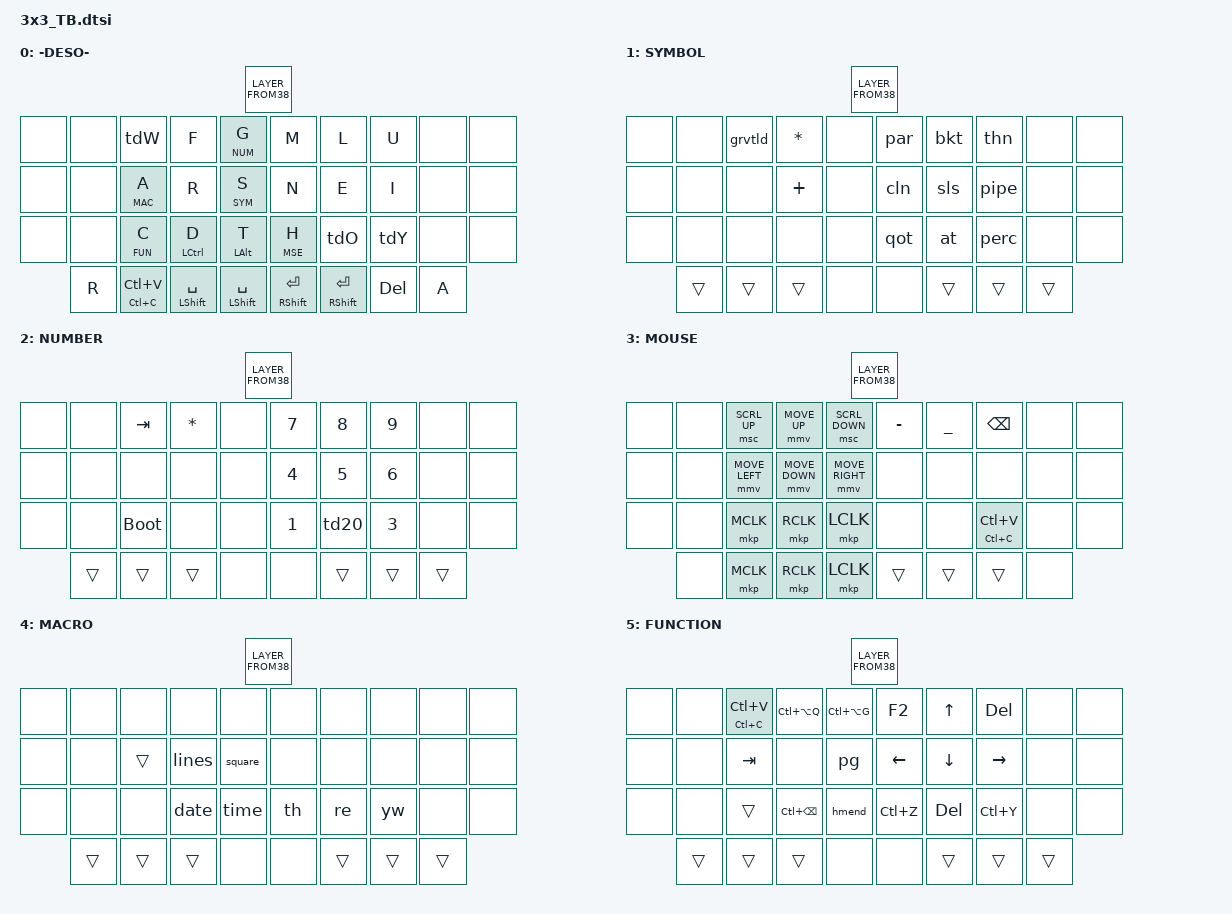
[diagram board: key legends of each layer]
/*
 * Last Update 10/5/24
 * 3 COL - 4 thumb keys per side
 * 
 */
 
#include <behaviors.dtsi>
#include <dt-bindings/zmk/keys.h>
#include <dt-bindings/zmk/bt.h>
#include <dt-bindings/zmk/outputs.h>
#include <dt-bindings/zmk/mouse.h>
#include "combos.dtsi"
#ifdef MOUSE_KEYS
#    include "mouse.dtsi"
#    define MS_ACT(key) &lt MSE key
#else
#    define MS_ACT(key) &kp key
#endif

// Layer aliases
#define DEF 0
#define SYM 1
#define NUM 2
#define MSE 3
#define MAC 4
#define FUN 5


&mt {
    flavor = "hold-preferred";
    tapping-term-ms = <160>;
};

&lt {
    flavor = "balanced";
    tapping-term-ms = <150>;
};

/ {
    behaviors {

        bkt: tap_dance_bracket {
            compatible = "zmk,behavior-tap-dance";
            label = "tap_dance_bracket";
            #binding-cells = <0>;
            tapping-term-ms = <200>;
            bindings = <&kp LBKT>, <&kp RBKT>;
        };

        cln: tap_dance_colon {
            compatible = "zmk,behavior-tap-dance";
            label = "tap_dance_colon";
            #binding-cells = <0>;
            tapping-term-ms = <200>;
            bindings = <&kp COLON>, <&kp SEMI>;
        };

        par: tap_dance_paren {
            compatible = "zmk,behavior-tap-dance";
            label = "tap_dance_paren";
            #binding-cells = <0>;
            tapping-term-ms = <200>;
            bindings = <&kp LPAR>, <&kp RPAR>;
        };

        thn: tap_dance_then {
            compatible = "zmk,behavior-tap-dance";
            label = "tap_dance_then";
            #binding-cells = <0>;
            tapping-term-ms = <200>;
            bindings = <&kp LT>, <&kp GT>;
        };

        qot: tap_dance_quote {
            compatible = "zmk,behavior-tap-dance";
            label = "tap_dance_quote";
            #binding-cells = <0>;
            tapping-term-ms = <200>;
            bindings = <&kp SQT>, <&kp DQT>;
        };

        sls: tap_dance_slash {
            compatible = "zmk,behavior-tap-dance";
            label = "tap_dance_slash";
            #binding-cells = <0>;
            tapping-term-ms = <200>;
            bindings = <&kp FSLH>, <&kp BSLH>;
        };

        pipe: tap_dance_pipe {
            compatible = "zmk,behavior-tap-dance";
            label = "tap_dance_pipe";
            #binding-cells = <0>;
            tapping-term-ms = <200>;
            bindings = <&kp PIPE>, <&kp AMPS>;
        };

        at: tap_dance_at {
            compatible = "zmk,behavior-tap-dance";
            label = "tap_dance_at";
            #binding-cells = <0>;
            tapping-term-ms = <200>;
            bindings = <&kp AT>, <&kp HASH>;
        };

        grvtld: tap_dance_gravetilde {
            compatible = "zmk,behavior-tap-dance";
            label = "tap_dance_gravetilde";
            #binding-cells = <0>;
            tapping-term-ms = <200>;
            bindings = <&kp GRAVE>, <&kp TILDE>;
        };

        perc: tap_dance_perc {
            compatible = "zmk,behavior-tap-dance";
            label = "tap_dance_perc";
            #binding-cells = <0>;
            tapping-term-ms = <200>;
            bindings = <&kp PRCNT>, <&kp DLLR>;
        };

        pg: tap_dance_pg {
            compatible = "zmk,behavior-tap-dance";
            label = "tap_dance_pg";
            #binding-cells = <0>;
            tapping-term-ms = <200>;
            bindings = <&kp PG_DN>, <&kp PG_UP>;
        };

        hmend: tap_dance_hmend {
            compatible = "zmk,behavior-tap-dance";
            label = "tap_dance_hmend";
            #binding-cells = <0>;
            tapping-term-ms = <200>;
            bindings = <&kp END>, <&kp HOME>;
        };

        tdW: tap_dance_W {
            compatible = "zmk,behavior-tap-dance";
            #binding-cells = <0>;
            tapping-term-ms = <180>;
            bindings = <&kp W>, <&kp ESC>;
        };

        tdO: tap_dance_O {
            compatible = "zmk,behavior-tap-dance";
            #binding-cells = <0>;
            tapping-term-ms = <200>;
            bindings = <&kp O>, <&kp COMMA>;
        };

        tdY: tap_dance_Y {
            compatible = "zmk,behavior-tap-dance";
            #binding-cells = <0>;
            tapping-term-ms = <200>;
            bindings = <&kp Y>, <&kp DOT>;
        };

        td20: tap_dance_20 {
            compatible = "zmk,behavior-tap-dance";
            #binding-cells = <0>;
            tapping-term-ms = <200>;
            bindings = <&kp N2>, <&kp N0>;
        };

        cccv: copy_paste {
           compatible = "zmk,behavior-hold-tap";
           #binding-cells = <2>;
           flavor = "hold-preferred";
           tapping-term-ms = <200>;
            bindings = <&kp>, <&kp>;
        };

        hrm: homerow_mods {
            compatible = "zmk,behavior-hold-tap";
            #binding-cells = <2>;
            tapping-term-ms = <200>;
            quick-tap-ms = <0>;
            flavor = "tap-preferred";
            bindings = <&kp>, <&kp>;
        };
    };

    macros {
        th: ahk_th {
            compatible = "zmk,behavior-macro";
            #binding-cells = <0>;
            bindings
                = <&macro_tap &kp FSLH &kp FSLH &kp T &kp H>
                ;
        };

        re: ahk_re {
            compatible = "zmk,behavior-macro";
            #binding-cells = <0>;
            bindings
                = <&macro_tap &kp FSLH &kp FSLH &kp R &kp E>
                ;
        };

        yw: ahk_yw {
            compatible = "zmk,behavior-macro";
            #binding-cells = <0>;
            bindings
                = <&macro_tap &kp FSLH &kp FSLH &kp Y &kp W>
                ;
        };

        date: ahk_date {
            compatible = "zmk,behavior-macro";
            #binding-cells = <0>;
            bindings
                = <&macro_tap &kp FSLH &kp FSLH &kp A &kp N1 &kp N1>
                ;
        };

        time: ahk_time {
            compatible = "zmk,behavior-macro";
            #binding-cells = <0>;
            bindings
                = <&macro_tap &kp FSLH &kp FSLH &kp A &kp N1 &kp N2>
                ;
        };

        lines: ahk_lines {
            compatible = "zmk,behavior-macro";
            #binding-cells = <0>;
            bindings
                = <&macro_tap &kp FSLH &kp FSLH &kp A &kp N0 &kp N8>
                ;
        };

        square: ahk_square {
            compatible = "zmk,behavior-macro";
            #binding-cells = <0>;
            bindings
                = <&macro_tap &kp FSLH &kp FSLH &kp A &kp N0 &kp N9>
                ;
        };
    };

    keymap {
        compatible = "zmk,keymap";


// ---------------------------------------------------------------------------------------------------------------
// |   TAB   |    W   [Q]   F   [B]   G num|         |    X    |         |    M   [J]   L    |    U    |  BSPC   |
// |  SHIFT  | A macro[V]   R   [P]   S sym|         |    X    |         |    N   [K]   E   [!]   I    |  DEL    |
// |  XXXX   |  C  fn [Z]   D   [X]   T    |         |    X    |         | H mouse |  O tt,  |  Y  tt. |  XXXX   |
//                     |   CCCV  |SPC/SHFT | RETURN  |    X    |   SPC   | SPC/ENT |   Paste |
// ---------------------------------------------------------------------------------------------------------------
        default_layer {
            display-name = "-DESO-";            
            bindings = <LAYER_FROM38( \
                &none, &none, &tdW, &kp F, &lt NUM G, &kp M, &kp L, &kp U, &none, &none, \
                &none, &none, &lt MAC A, &kp R, &lt SYM S, &kp N, &kp E, &kp I, &none, &none, \
                &none, &none, &lt FUN C, &hrm LCTRL D, &hrm LALT T, &lt MSE H, &tdO, &tdY, &none, &none, \
                &kp R, &cccv LC(C) LC(V), &mt LSHIFT SPC, &mt LSHIFT SPC, &mt RSHIFT RET, &mt RSHIFT RET,  &kp DEL, &kp A \
            )>;
        };

        SYM_layer {
            display-name = "SYMBOL";
            bindings = <LAYER_FROM38( \
                &none, &none, &grvtld, &kp STAR, &none, &par, &bkt, &thn, &none, &none, \
                &none, &none, &none, &kp PLUS, &none, &cln, &sls, &pipe, &none, &none, \
                &none, &none, &none, &none, &none, &qot, &at, &perc, &none, &none, \
                &trans, &trans, &trans, &none, &none, &trans, &trans,  &trans \
            )>;
        };

        NUM_layer {
            display-name = "NUMBER";
            bindings = <LAYER_FROM38( \
                &none, &none, &kp TAB, &kp STAR, &none, &kp N7, &kp N8, &kp N9, &none, &none, \
                &none, &none, &none, &none, &none, &kp N4, &kp N5, &kp N6, &none, &none, \
                &none, &none, &bootloader, &none, &none, &kp N1, &td20, &kp N3, &none, &none, \
                       &trans, &trans, &trans, &none, &none, &trans, &trans, &trans \
            )>;
        };

        MOUSE_layer {
            display-name = "MOUSE";
            bindings = <LAYER_FROM38( \
                &none, &none, &msc SCRL_UP, &mmv MOVE_UP, &msc SCRL_DOWN, &kp MINUS, &kp UNDER, &kp BSPC, &none, &none, \
                &none, &none, &mmv MOVE_LEFT, &mmv MOVE_DOWN, &mmv MOVE_RIGHT, &none, &none, &none, &none, &none, \
                &none, &none, &mkp MCLK, &mkp RCLK, &mkp LCLK, &none, &none, &cccv LC(C) LC(V), &none, &none, \
                      &none, &mkp MCLK, &mkp RCLK, &mkp LCLK, &trans, &trans, &trans, &none \
            )>;
        };

        MACRO_layer {
            display-name = "MACRO";
            bindings = <LAYER_FROM38( \
                &none, &none, &none, &none, &none, &none, &none, &none, &none, &none, \
                &none, &none, &trans, &lines, &square, &none, &none, &none, &none, &none, \
                &none, &none, &none, &date, &time, &th, &re, &yw, &none, &none, \
                      &trans, &trans, &trans, &none, &none, &trans, &trans, &trans \
            )>;
        };

        FN_layer {
            display-name = "FUNCTION";    
            bindings = <LAYER_FROM38( \
                &none, &none, &cccv LC(C) LC(V), &kp LC(LA(Q)), &kp LC(LA(G)), &kp F2, &kp UP, &kp DEL, &none, &none, \
                &none, &none, &kp TAB, &none, &pg, &kp LEFT, &kp DOWN, &kp RIGHT, &none, &none, \
                &none, &none, &trans, &kp LC(BSPC), &hmend, &kp LC(Z), &kp DEL, &kp LC(Y), &none, &none, \
                      &trans, &trans, &trans, &none, &none, &trans, &trans, &trans \
            )>;
        };
    };
